# haltium_application register map
Vendor: Nordic Semiconductor; Series: nRFHaltium; File version: 1
CPU: CM33 r0p4, little endian, MPU, FPU, 3 interrupt priority bits, 480 interrupts
Registers are 32-bit, read-write, reset 0x0 unless marked. A register's access mark holds for its fields unless they carry their own. Offsets are from the block's base; [hi:lo] are bit positions; lines under a group give offsets from that group; {n}, {i} and the like mark numbered series.

## CPUCONF_NS — CPU Configuration 0
Base 0x42011000
Same registers: CPUCONF_S 0x52011000
0x00 TASKS_ERASECACHE wo — Erase the caches used by the CPU.
  [0] TASKS_ERASECACHE
    1=Trigger task
0x500 INITSVTOR — Initial value of the secure VTOR (Vector Table Offset Register) after CPU reset.
  [31:0] INITSVTOR — Initial value of the VTOR.
0x504 INITNSVTOR — Initial value of the non-secure VTOR (Vector Table Offset Register).
  [31:0] INITNSVTOR — Initial value of the VTOR.
0x508 CPUSTART — Enable for starting the CPU
  [0] EN — Enable to start the CPU.
    0=Stopped (CPU stopped.); 1=Started (CPU started.)
0x50C CPUWAIT — Enable for the CPU wait.
  [0] EN — Enable to the CPU wait.
    0=Disabled (CPU is not waiting.); 1=Enabled (CPU is waiting.)

## MEMCONF_NS — Memory configuration 0
Base 0x42012000
Same registers: MEMCONF_S 0x52012000
{0x500+0x10*i} POWER[{i}] (i=0..3) group — Unspecified
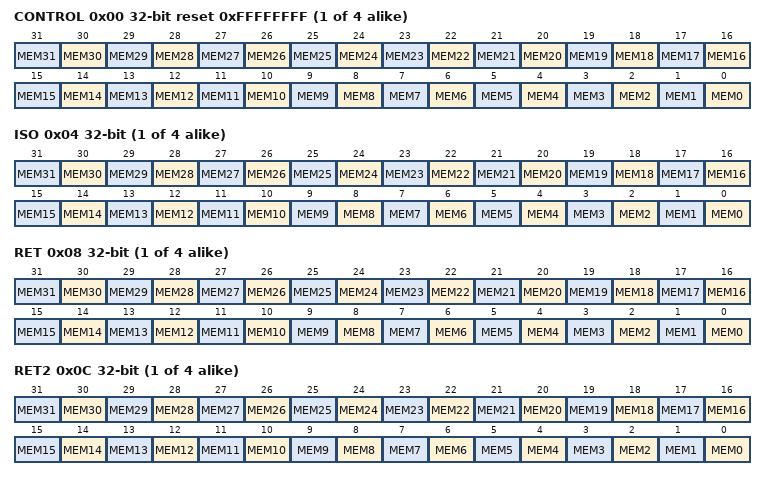
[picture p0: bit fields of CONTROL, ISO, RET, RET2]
  0x00 CONTROL reset 0xFFFFFFFF — Description cluster: RAM/ROM[n] power control register.
    [all] fields
      0=Off (Power down); 1=On (Power up)
    [n] MEM{n} (n=0..31) — Keep the RAM/ROM block MEM[{n}] on or off when in System ON mode.
  0x04 ISO — Description cluster: RAM/ROM [n] power isolation control register.
    [all] fields
      0=Off (Isolation off); 1=On (Isolation on)
    [n] MEM{n} (n=0..31) — Turn on/off the power isolation for RAM/ROM block MEM[{n}].
  0x08 RET — Description cluster: RAM retention for RAM/ROM [n].
    [all] fields
      0=Off (Retention off); 1=On (Retention on)
    [n] MEM{n} (n=0..31) — Keep the RAM block MEM[{n}] retained when in System OFF mode.
  0x0C RET2 — Description cluster: RAM retention for the second bank in the RAM block
    [all] fields
      0=Off (Retention off); 1=On (Retention on)
    [n] MEM{n} (n=0..31) — Keep the second bank in RAM block MEM[{n}] retained when in System OFF mode.
{0x600+0x18*i} REPAIR[{i}] (i=0..31) group — Unspecified
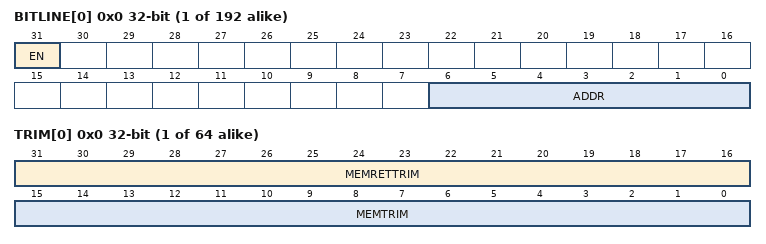
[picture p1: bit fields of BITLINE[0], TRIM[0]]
  {0x0+4j} BITLINE[{j}] (j=0..5) — Description collection: RAM repair bitline configuration RAM/ROM blocks.
    [31] EN — Enable bitline repair
      0=Disabled (Repair disabled.); 1=Enabled (Repair enabled.)
    [6:0] ADDR — Repair address of the bitline
0x900 BLOCKTYPE group — Unspecified
  {0x0+4j} TRIM[{j}] (j=0..63) — Description collection: Trim configuration for the RAM/ROM block types.
    [31:16] MEMRETTRIM — Trimming for retention mode for decreased leakage. Must be kept active in RAM retention mode.
    [15:0] MEMTRIM — Read/write margin trim.

## BELLBOARD_NS — BELLBOARD APB registers 0
Base 0x4F09A000
Same registers: BELLBOARD_S 0x5F09A000
{0x0+4i} TASKS_SIGNAL[{i}] (i=0..31) wo — Description collection: Signal [n] task
  [0] TASKS_SIGNAL — Signal [n] task
    1=Trigger task
{0x100+4i} EVENTS_SIGNALSET[{i}] (i=0..31) — Description collection: Signal set [n] event
  [0] EVENTS_SIGNALSET — Signal set [n] event
    0=NotGenerated (Event not generated); 1=Generated (Event generated)
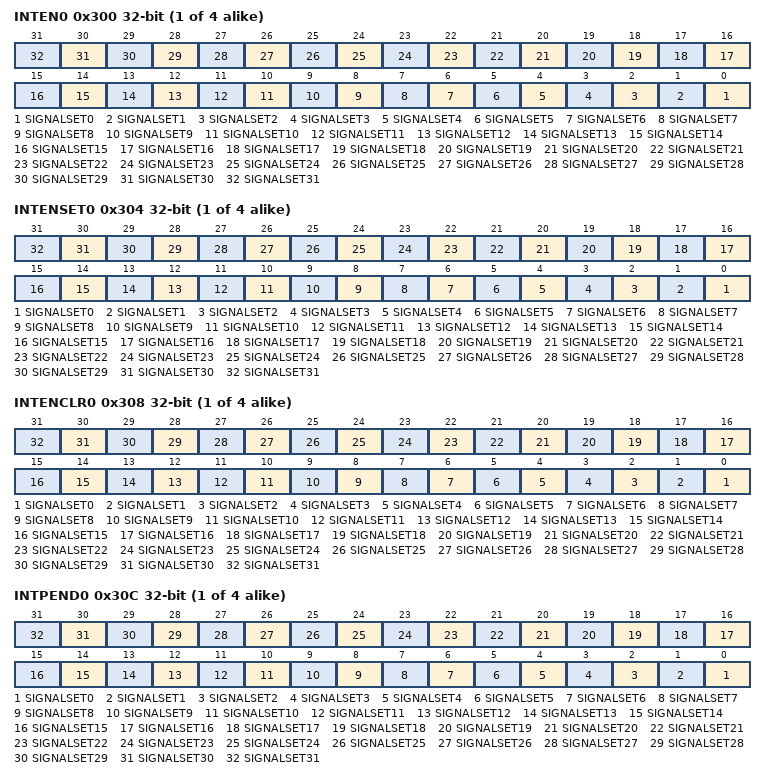
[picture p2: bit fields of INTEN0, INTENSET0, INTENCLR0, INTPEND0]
{0x300+0x10*i} INTEN{i} (i=0..3) — Enable or disable interrupt
  [all] fields
    0=Disabled; 1=Enabled
  [n] SIGNALSET{n} (n=0..31) — Enable or disable interrupt for event SIGNALSET[{n}]
{0x304+0x10*i} INTENSET{i} (i=0..3) — Enable interrupt
  [all] fields
    on read: 0=Disabled (Read: Disabled); 1=Enabled (Read: Enabled) | on write: 1=Set (Enable)
  [n] SIGNALSET{n} (n=0..31) — Write '1' to enable interrupt for event SIGNALSET[{n}]
{0x308+0x10*i} INTENCLR{i} (i=0..3) — Disable interrupt
  [all] fields
    on read: 0=Disabled (Read: Disabled); 1=Enabled (Read: Enabled) | on write: 1=Clear (Disable)
  [n] SIGNALSET{n} (n=0..31) — Write '1' to disable interrupt for event SIGNALSET[{n}]
{0x30C+0x10*i} INTPEND{i} ro (i=0..3) — Pending interrupts
  [all] fields
    on read: 0=NotPending (Read: Not pending); 1=Pending (Read: Pending)
  [n] SIGNALSET{n} (n=0..31) — Read pending status of interrupt for event SIGNALSET[{n}]
